# STM32U345xx register map
File version: 1.0
Registers are 32-bit, read-write, reset 0x0 unless marked. A register's access mark holds for its fields unless they carry their own. Offsets are from the block's base; [hi:lo] are bit positions; {n}, {i} and the like mark numbered series.

## RNG
Base 0x420C0800
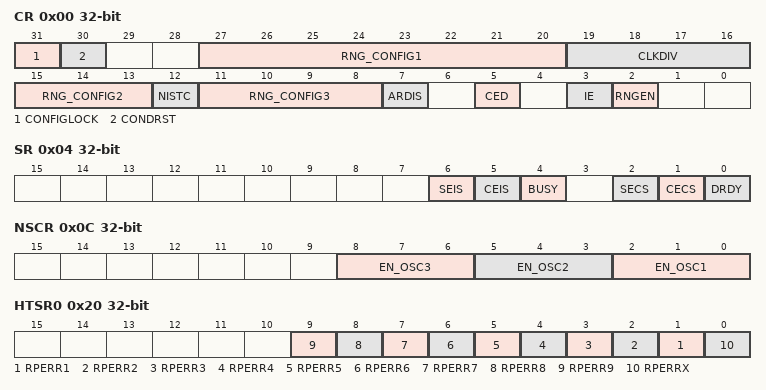
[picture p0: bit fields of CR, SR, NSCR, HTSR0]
0x00 CR — RNG control register
  [31] CONFIGLOCK — RNG configuration lock
  [30] CONDRST — Conditioning soft reset
  [27:20] RNG_CONFIG1 — RNG configuration 1
  [19:16] CLKDIV — Clock divider factor
    0=BY_1 (No clock division); 1=BY_2 (2 RNG clock cycles per internal RNG clock); 2=BY_4 (4 RNG clock cycles per internal RNG clock); 3=BY_8 (8 RNG clock cycles per internal RNG clock); 4=BY_16 (16 RNG clock cycles per internal RNG clock); 5=BY_32 (32 RNG clock cycles per internal RNG clock); 6=BY_64 (64 RNG clock cycles per internal RNG clock); 7=BY_128 (128 RNG clock cycles per internal RNG clock); 8=BY_256 (256 RNG clock cycles per internal RNG clock); 9=BY_512 (512 RNG clock cycles per internal RNG clock); 10=BY_1024 (1024 RNG clock cycles per internal RNG clock); 11=BY_2048 (2048 RNG clock cycles per internal RNG clock); 12=BY_4096 (4096 RNG clock cycles per internal RNG clock); 13=BY_8192 (8192 RNG clock cycles per internal RNG clock); 14=BY_16384 (16384 RNG clock cycles per internal RNG clock); 15=BY_32768 (32768 RNG clock cycles per internal RNG clock)
  [15:13] RNG_CONFIG2 — RNG configuration 2
  [12] NISTC — NIST custom
  [11:8] RNG_CONFIG3 — RNG configuration 3
  [7] ARDIS — Auto reset disable
  [5] CED — Clock error detection
  [3] IE — Interrupt enable
  [2] RNGEN — True random number generator enable
0x04 SR — RNG status register
  [6] SEIS, [5] CEIS, [4] BUSY, [2] SECS, [1] CECS, [0] DRDY
0x08 DR — RNG data register
0x0C NSCR — RNG noise source control register
  [8:6] EN_OSC3, [5:3] EN_OSC2, [2:0] EN_OSC1
{0x10+4i} HTCR{i} (i=0..3) — RNG health test configuration register
  [31:0] HTCFG
0x20 HTSR0 — RNG health test status register
  [n] RPERR{n} (n=1..9) — Repetitive error for oscillator i
  [0] RPERRX — Repetitive error after the XOR
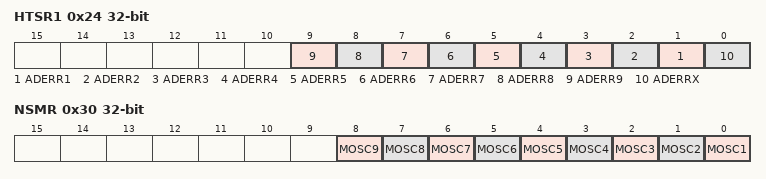
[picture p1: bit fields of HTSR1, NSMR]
0x24 HTSR1 — RNG health test status register
  [n] ADERR{n} (n=1..9) — Adaptative error for oscillator i
  [0] ADERRX — Adaptative error after the XOR
0x30 NSMR — RNG health test status register
  [n-1] MOSC{n} (n=1..9) — Mask oscillator i

## DLYB_OCTOSPI1
Base 0x420CF000
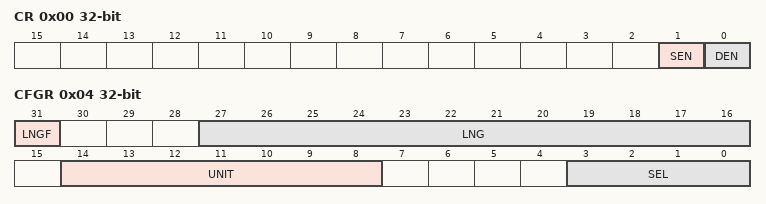
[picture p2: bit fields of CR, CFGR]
0x00 CR — Delay Block Control Register
  [1] SEN — Sampler length enable
  [0] DEN — Delay Block enable
0x04 CFGR — Delay Block Configuration Register
  [31] LNGF — Length valid flag
  [27:16] LNG — Delay line length value[11:0]
  [14:8] UNIT — Delay Defines the delay of a Unit delay cell[6:0]
  [3:0] SEL — Select the phase for the Output clock[3:0]

## DBGMCU — Debug MCU
Base 0xE0044000
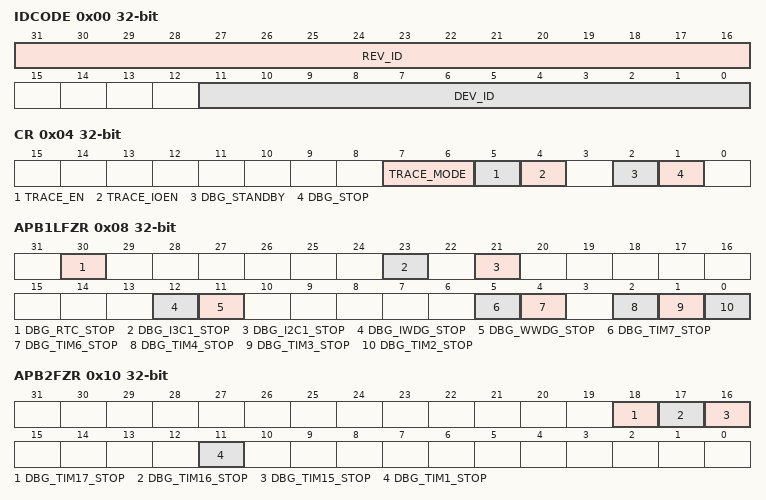
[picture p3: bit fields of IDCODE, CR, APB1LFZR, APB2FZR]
0x00 IDCODE — MCU device ID code
  [31:16] REV_ID, [11:0] DEV_ID
0x04 CR — Debug MCU configuration register
  [7:6] TRACE_MODE, [5] TRACE_EN, [4] TRACE_IOEN, [2] DBG_STANDBY, [1] DBG_STOP
0x08 APB1LFZR — Debug MCU APB1L freeze register
  [30] DBG_RTC_STOP, [23] DBG_I3C1_STOP, [21] DBG_I2C1_STOP, [12] DBG_IWDG_STOP, [11] DBG_WWDG_STOP, [5] DBG_TIM7_STOP, [4] DBG_TIM6_STOP, [2] DBG_TIM4_STOP, [1] DBG_TIM3_STOP, [0] DBG_TIM2_STOP
0x0C APB1HFZR — Debug MCU APB1H freeze register
  [5] DBG_LPTIM2_STOP
0x10 APB2FZR — Debug MCU APB2 freeze register
  [18] DBG_TIM17_STOP, [17] DBG_TIM16_STOP, [16] DBG_TIM15_STOP, [11] DBG_TIM1_STOP
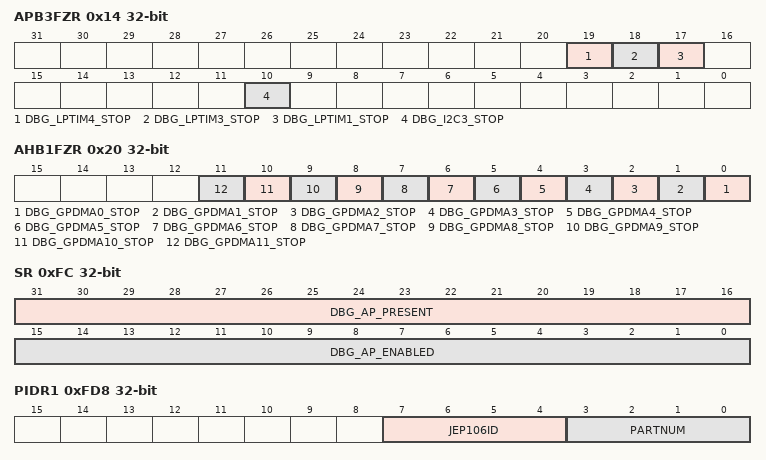
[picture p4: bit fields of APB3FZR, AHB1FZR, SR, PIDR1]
0x14 APB3FZR — Debug MCU APB3 freeze register
  [19] DBG_LPTIM4_STOP, [18] DBG_LPTIM3_STOP, [17] DBG_LPTIM1_STOP, [10] DBG_I2C3_STOP
0x20 AHB1FZR — Debug MCU AHB1 freeze register
  [n] DBG_GPDMA{n}_STOP (n=0..11)
0xFC SR — Debug MCU status register
  [31:16] DBG_AP_PRESENT, [15:0] DBG_AP_ENABLED
0x100 DGB_AUTH_HOST — Debug MCU debug host authentication register
0x104 DGB_AUTH_DEVICE — Debug MCU debug device authentication register
0xFD0 PIDR4 — Debug MCU CoreSight peripheral identity register 4
  [3:0] JEP106CON
0xFD4 PIDR0 — Debug MCU CoreSight peripheral identity register 0
  [7:0] PARTNUM
0xFD8 PIDR1 — Debug MCU CoreSight peripheral identity register 1
  [7:4] JEP106ID, [3:0] PARTNUM
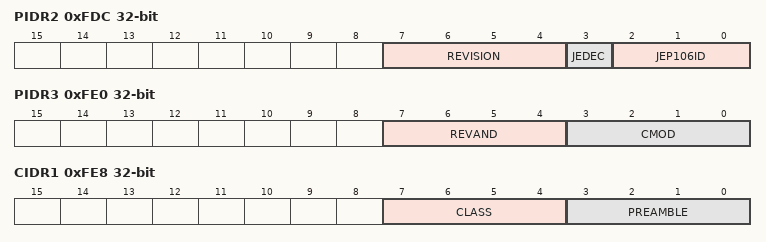
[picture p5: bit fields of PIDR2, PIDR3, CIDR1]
0xFDC PIDR2 — Debug MCU CoreSight peripheral identity register 2
  [7:4] REVISION, [3] JEDEC, [2:0] JEP106ID
0xFE0 PIDR3 — Debug MCU CoreSight peripheral identity register 3
  [7:4] REVAND, [3:0] CMOD
0xFE4 CIDR0 — Debug MCU CoreSight component identity register 0
  [7:0] PREAMBLE
0xFE8 CIDR1 — Debug MCU CoreSight component identity register 1
  [7:4] CLASS, [3:0] PREAMBLE
0xFEC CIDR2 — Debug MCU CoreSight component identity register 2
  [7:0] PREAMBLE
0xFF0 CIDR3 — Debug MCU CoreSight component identity register 3
  [7:0] PREAMBLE
